# HDSC_HC32F451 register map
Vendor: HDSC; Series: ARMCM4; File version: 1.0
CPU: CM4 r0p1, little endian, MPU, FPU, 4 interrupt priority bits
Registers are 32-bit, read-write, reset 0x0 unless marked. A register's access mark holds for its fields unless they carry their own. Offsets are from the block's base; [hi:lo] are bit positions; {n}, {i} and the like mark numbered series.

## AES
Base 0x40008000
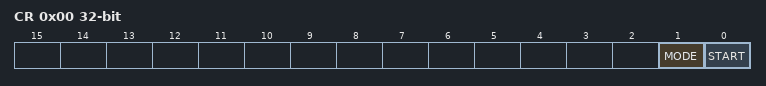
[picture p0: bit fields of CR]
0x00 CR
  [1] MODE, [0] START
{0x10+4i} DR{i} (i=0..3)
{0x20+4i} KR{i} (i=0..3)

## AOS
Base 0x40010800
0x00 INTSFTTRG wo
  [0] STRG
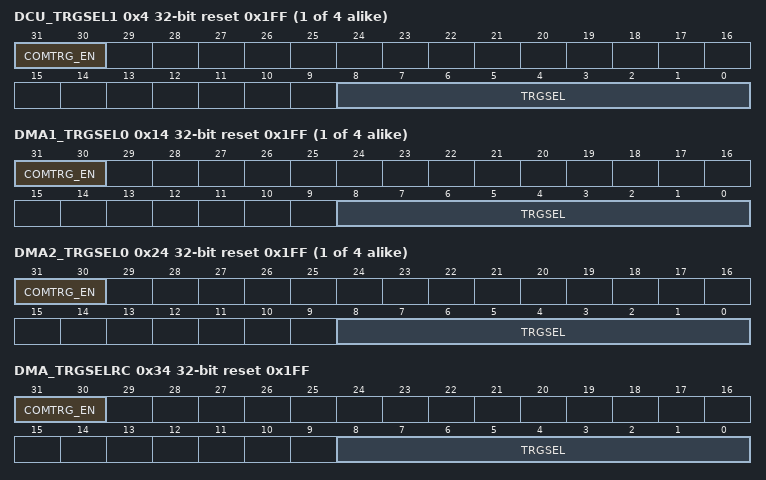
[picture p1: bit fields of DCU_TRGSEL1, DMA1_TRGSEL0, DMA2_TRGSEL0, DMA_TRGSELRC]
{0x0+4i} DCU_TRGSEL{i} reset 0x1FF (i=1..4)
  [31:30] COMTRG_EN, [8:0] TRGSEL
{0x14+4i} DMA1_TRGSEL{i} reset 0x1FF (i=0..3)
  [31:30] COMTRG_EN, [8:0] TRGSEL
{0x24+4i} DMA2_TRGSEL{i} reset 0x1FF (i=0..3)
  [31:30] COMTRG_EN, [8:0] TRGSEL
0x34 DMA_TRGSELRC reset 0x1FF
  [31:30] COMTRG_EN, [8:0] TRGSEL
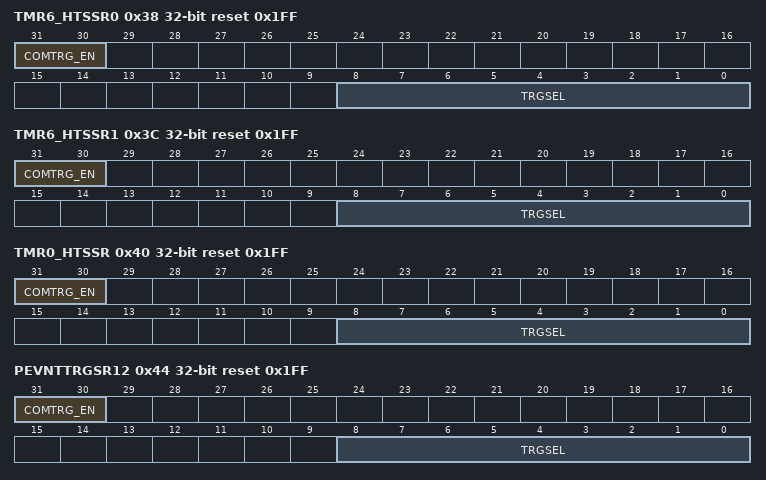
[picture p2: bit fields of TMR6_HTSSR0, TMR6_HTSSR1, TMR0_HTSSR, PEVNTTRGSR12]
0x38 TMR6_HTSSR0 reset 0x1FF
  [31:30] COMTRG_EN, [8:0] TRGSEL
0x3C TMR6_HTSSR1 reset 0x1FF
  [31:30] COMTRG_EN, [8:0] TRGSEL
0x40 TMR0_HTSSR reset 0x1FF
  [31:30] COMTRG_EN, [8:0] TRGSEL
0x44 PEVNTTRGSR12 reset 0x1FF
  [31:30] COMTRG_EN, [8:0] TRGSEL
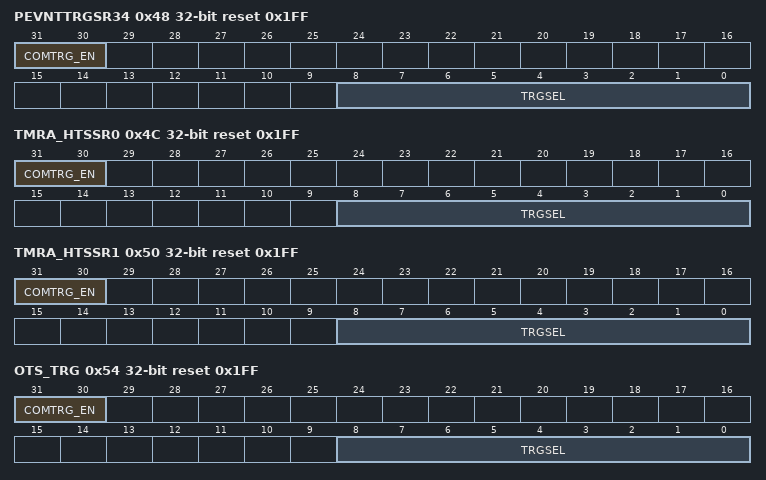
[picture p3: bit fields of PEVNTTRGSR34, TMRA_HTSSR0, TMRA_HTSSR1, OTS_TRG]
0x48 PEVNTTRGSR34 reset 0x1FF
  [31:30] COMTRG_EN, [8:0] TRGSEL
0x4C TMRA_HTSSR0 reset 0x1FF
  [31:30] COMTRG_EN, [8:0] TRGSEL
0x50 TMRA_HTSSR1 reset 0x1FF
  [31:30] COMTRG_EN, [8:0] TRGSEL
0x54 OTS_TRG reset 0x1FF
  [31:30] COMTRG_EN, [8:0] TRGSEL
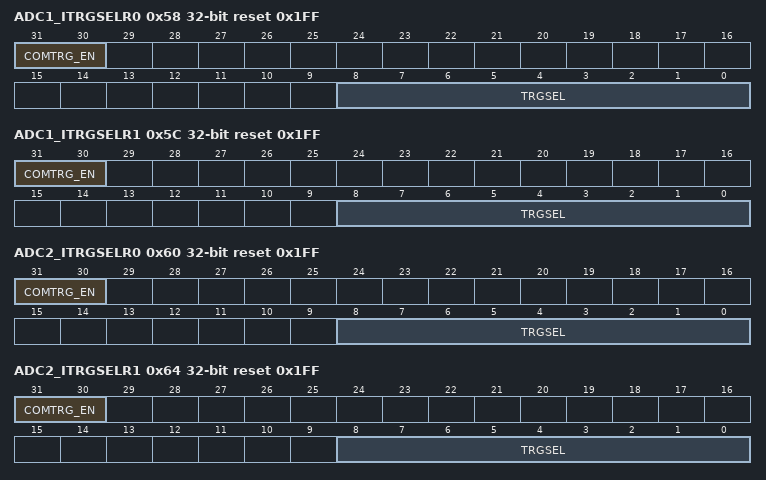
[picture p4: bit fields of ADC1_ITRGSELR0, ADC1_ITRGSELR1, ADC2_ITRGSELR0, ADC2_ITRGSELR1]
0x58 ADC1_ITRGSELR0 reset 0x1FF
  [31:30] COMTRG_EN, [8:0] TRGSEL
0x5C ADC1_ITRGSELR1 reset 0x1FF
  [31:30] COMTRG_EN, [8:0] TRGSEL
0x60 ADC2_ITRGSELR0 reset 0x1FF
  [31:30] COMTRG_EN, [8:0] TRGSEL
0x64 ADC2_ITRGSELR1 reset 0x1FF
  [31:30] COMTRG_EN, [8:0] TRGSEL
0x68 COMTRG1 reset 0x1FF
  [8:0] TRGSEL
0x6C COMTRG2 reset 0x1FF
  [8:0] TRGSEL
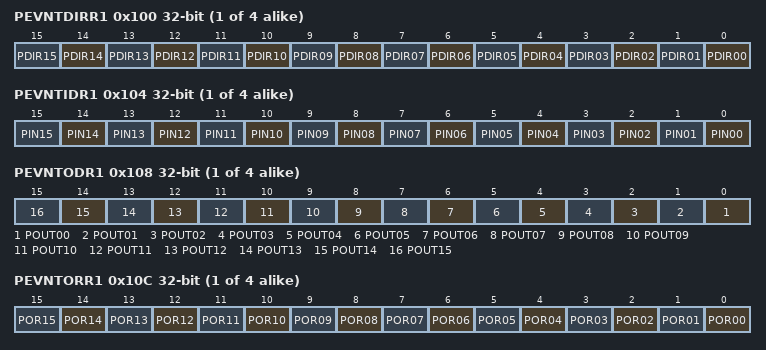
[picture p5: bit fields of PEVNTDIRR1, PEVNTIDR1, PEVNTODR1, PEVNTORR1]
{0xE4+0x1C*i} PEVNTDIRR{i} (i=1..4)
  [n] PDIR{n:02} (n=0..15)
{0xE8+0x1C*i} PEVNTIDR{i} ro (i=1..4)
  [n] PIN{n:02} (n=0..15)
{0xEC+0x1C*i} PEVNTODR{i} (i=1..4)
  [n] POUT{n:02} (n=0..15)
{0xF0+0x1C*i} PEVNTORR{i} (i=1..4)
  [n] POR{n:02} (n=0..15)
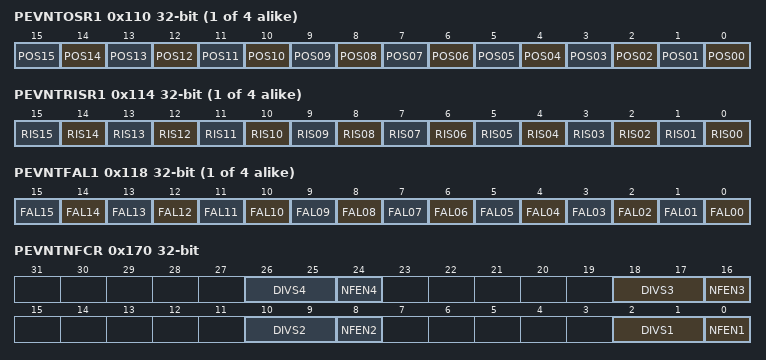
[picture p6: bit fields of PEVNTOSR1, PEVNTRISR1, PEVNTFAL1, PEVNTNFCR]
{0xF4+0x1C*i} PEVNTOSR{i} (i=1..4)
  [n] POS{n:02} (n=0..15)
{0xF8+0x1C*i} PEVNTRISR{i} (i=1..4)
  [n] RIS{n:02} (n=0..15)
{0xFC+0x1C*i} PEVNTFAL{i} (i=1..4)
  [n] FAL{n:02} (n=0..15)
0x170 PEVNTNFCR
  [8n-6:8n-7] DIVS{n} (n=1..4), [8n-8] NFEN{n} (n=1..4)

## CMP1 — desc CMP
Base 0x4004A000
Same registers: CMP2 0x4004A010, CMP3 0x4004A020
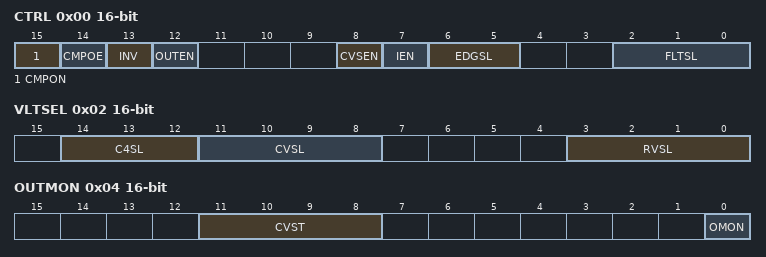
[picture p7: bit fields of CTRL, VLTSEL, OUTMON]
0x00 CTRL 16-bit
  [15] CMPON, [14] CMPOE, [13] INV, [12] OUTEN, [8] CVSEN, [7] IEN, [6:5] EDGSL, [2:0] FLTSL
0x02 VLTSEL 16-bit
  [14:12] C4SL, [11:8] CVSL, [3:0] RVSL
0x04 OUTMON 16-bit ro
  [11:8] CVST, [0] OMON
0x06 CVSSTB 16-bit reset 0x5
  [3:0] STB
0x08 CVSPRD 16-bit reset 0xF
  [7:0] PRD

## CMPCR
Base 0x4004A000; alternate view of CMP1
0x100 DADR1 16-bit
  [7:0] DATA
0x102 DADR2 16-bit
  [7:0] DATA
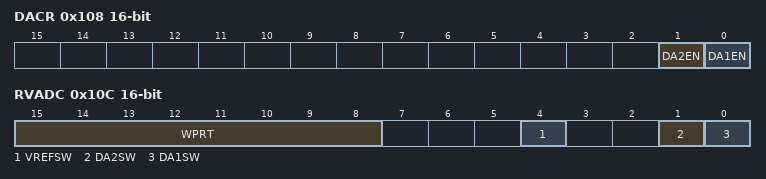
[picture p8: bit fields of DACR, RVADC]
0x108 DACR 16-bit
  [1] DA2EN, [0] DA1EN
0x10C RVADC 16-bit (reset mask 0x13)
  [15:8] WPRT, [4] VREFSW, [1] DA2SW, [0] DA1SW

## CMU
Base 0x40054000
0x10 PERICKSEL 16-bit
  [3:0] PERICKSEL
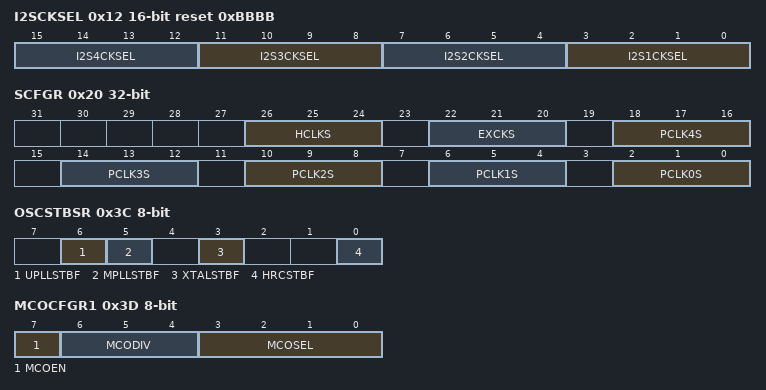
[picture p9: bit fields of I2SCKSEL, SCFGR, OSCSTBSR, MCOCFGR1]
0x12 I2SCKSEL 16-bit reset 0xBBBB
  [4n-1:4n-4] I2S{n}CKSEL (n=1..4)
0x20 SCFGR
  [26:24] HCLKS, [22:20] EXCKS, [4n+2:4n] PCLK{n}S (n=0..4)
0x24 USBCKCFGR 8-bit reset 0x40
  [7:4] USBCKS
0x26 CKSWR 8-bit reset 0x1
  [2:0] CKSW
0x2A PLLCR 8-bit reset 0x1
  [0] MPLLOFF
0x2E UPLLCR 8-bit reset 0x1
  [0] UPLLOFF
0x32 XTALCR 8-bit reset 0x1
  [0] XTALSTP
0x36 HRCCR 8-bit reset 0x1
  [0] HRCSTP
0x38 MRCCR 8-bit reset 0x80
  [0] MRCSTP
0x3C OSCSTBSR 8-bit
  [6] UPLLSTBF, [5] MPLLSTBF, [3] XTALSTBF, [0] HRCSTBF
0x3D MCOCFGR1 8-bit
  [7] MCOEN, [6:4] MCODIV, [3:0] MCOSEL
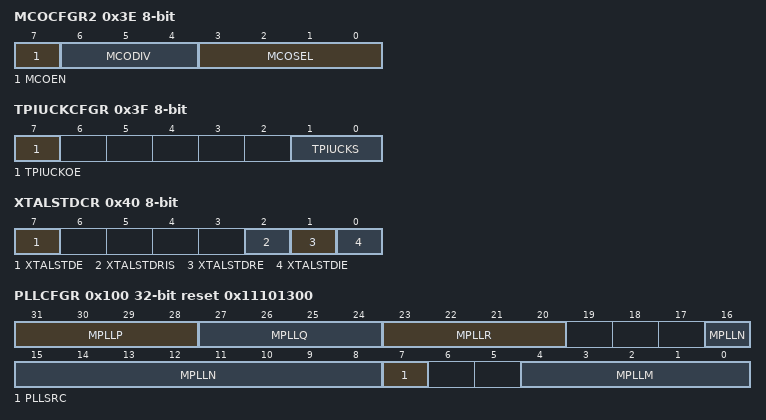
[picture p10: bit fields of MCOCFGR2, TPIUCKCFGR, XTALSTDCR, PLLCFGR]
0x3E MCOCFGR2 8-bit
  [7] MCOEN, [6:4] MCODIV, [3:0] MCOSEL
0x3F TPIUCKCFGR 8-bit
  [7] TPIUCKOE, [1:0] TPIUCKS
0x40 XTALSTDCR 8-bit
  [7] XTALSTDE, [2] XTALSTDRIS, [1] XTALSTDRE, [0] XTALSTDIE
0x41 XTALSTDSR 8-bit
  [0] XTALSTDF
0x61 MRCTRM 8-bit
0x62 HRCTRM 8-bit
0xA2 XTALSTBCR 8-bit reset 0x5
  [3:0] XTALSTB
0x100 PLLCFGR reset 0x11101300
  [31:28] MPLLP, [27:24] MPLLQ, [23:20] MPLLR, [16:8] MPLLN, [7] PLLSRC, [4:0] MPLLM
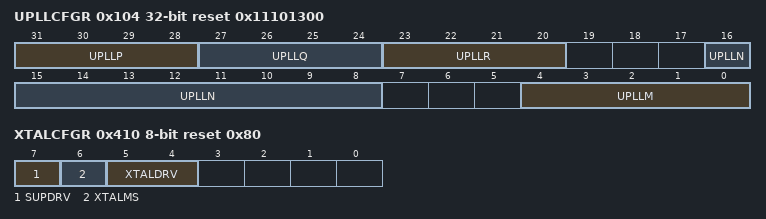
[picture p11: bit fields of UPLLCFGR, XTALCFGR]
0x104 UPLLCFGR reset 0x11101300
  [31:28] UPLLP, [27:24] UPLLQ, [23:20] UPLLR, [16:8] UPLLN, [4:0] UPLLM
0x410 XTALCFGR 8-bit reset 0x80
  [7] SUPDRV, [6] XTALMS, [5:4] XTALDRV
0x420 XTAL32CR 8-bit
  [0] XTAL32STP
0x421 XTAL32CFGR 8-bit
  [2:0] XTAL32DRV
0x425 XTAL32NFR 8-bit
  [1:0] XTAL32NF
0x427 LRCCR 8-bit
  [0] LRCSTP
0x429 LRCTRM 8-bit
